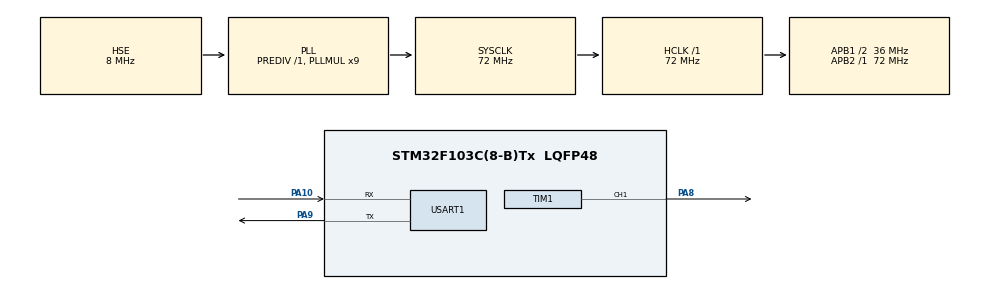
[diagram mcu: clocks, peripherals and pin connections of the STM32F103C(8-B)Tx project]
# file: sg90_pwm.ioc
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Mcu.Family=STM32F1
Mcu.Name=STM32F103C(8-B)Tx
Mcu.Package=LQFP48
NVIC.PriorityGroup=NVIC_PRIORITYGROUP_4
NVIC.USART1_IRQn=true\:0\:0\:false\:false\:true\:true\:true\:true
PA10.Mode=Asynchronous
PA10.Signal=USART1_RX
PA13.Mode=Serial_Wire
PA13.Signal=SYS_JTMS-SWDIO
PA14.Mode=Serial_Wire
PA14.Signal=SYS_JTCK-SWCLK
PA8.Signal=S_TIM1_CH1
PA9.Mode=Asynchronous
PA9.Signal=USART1_TX
PD0-OSC_IN.Mode=HSE-External-Oscillator
PD0-OSC_IN.Signal=RCC_OSC_IN
PD1-OSC_OUT.Mode=HSE-External-Oscillator
PD1-OSC_OUT.Signal=RCC_OSC_OUT
ProjectManager.HeapSize=0x200
ProjectManager.StackSize=0x400
ProjectManager.TargetToolchain=MDK-ARM V5.32
RCC.AHBFreq_Value=72000000
RCC.APB1CLKDivider=RCC_HCLK_DIV2
RCC.APB1Freq_Value=36000000
RCC.APB1TimFreq_Value=72000000
RCC.APB2Freq_Value=72000000
RCC.APB2TimFreq_Value=72000000
RCC.HCLKFreq_Value=72000000
RCC.PLLMUL=RCC_PLL_MUL9
RCC.PLLSourceVirtual=RCC_PLLSOURCE_HSE
RCC.SYSCLKFreq_VALUE=72000000
RCC.SYSCLKSource=RCC_SYSCLKSOURCE_PLLCLK
RCC.USBFreq_Value=72000000
SH.S_TIM1_CH1.0=TIM1_CH1,PWM Generation1 CH1
TIM1.AutoReloadPreload=TIM_AUTORELOAD_PRELOAD_ENABLE
TIM1.Channel-PWM\ Generation1\ CH1=TIM_CHANNEL_1
TIM1.OCFastMode_PWM-PWM\ Generation1\ CH1=TIM_OCFAST_ENABLE
TIM1.Period=19999
TIM1.Prescaler=71
TIM1.Pulse-PWM\ Generation1\ CH1=1000-1
USART1.VirtualMode=VM_ASYNC
board=custom

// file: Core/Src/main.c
/* USER CODE BEGIN Header */
/**
  ******************************************************************************
  * @file           : main.c
  * @brief          : Main program body
  ******************************************************************************
  * @attention
  *
  * Copyright (c) 2026 STMicroelectronics.
  * All rights reserved.
  *
  * This software is licensed under terms that can be found in the LICENSE file
  * in the root directory of this software component.
  * If no LICENSE file comes with this software, it is provided AS-IS.
  *
  ******************************************************************************
  */
/* USER CODE END Header */
#include "main.h"
#include "tim.h"
#include "usart.h"
#include "gpio.h"

/* USER CODE BEGIN Includes */
#include <string.h>
#include <stdlib.h>
#include <stdio.h>
/* USER CODE END Includes */

/* USER CODE BEGIN PV */
uint8_t rx_byte;
char rx_buf[32];
uint8_t rx_index =0;
/* USER CODE END PV */

void SystemClock_Config(void);
/* USER CODE BEGIN PFP */
void parse_command(char *cmd);   // 指令解析函数声明
/* USER CODE END PFP */

int main(void)
{

  /* MCU Configuration--------------------------------------------------------*/

  /* Reset of all peripherals, Initializes the Flash interface and the Systick. */
  HAL_Init();

  /* Configure the system clock */
  SystemClock_Config();

  /* Initialize all configured peripherals */
  MX_GPIO_Init();
  MX_TIM1_Init();
  MX_USART1_UART_Init();
  /* USER CODE BEGIN 2 */
  HAL_TIM_PWM_Start(&htim1, TIM_CHANNEL_1);
  HAL_UART_Receive_IT(&huart1, &rx_byte, 1);
  // 上电打印测试信息
  HAL_UART_Transmit(&huart1, (uint8_t*)"SG90 Servo Ready\r\n", 18, 100);
  /* USER CODE END 2 */

  /* Infinite loop */
  while (1)
  {

    /* USER CODE BEGIN 3 */
    // 什么都不用做，接收全部在中断回调里处理
  }
  /* USER CODE END 3 */
}

void SystemClock_Config(void)
{
  RCC_OscInitTypeDef RCC_OscInitStruct = {0};
  RCC_ClkInitTypeDef RCC_ClkInitStruct = {0};

  /** Initializes the RCC Oscillators according to the specified parameters
  * in the RCC_OscInitTypeDef structure.
  */
  RCC_OscInitStruct.OscillatorType = RCC_OSCILLATORTYPE_HSE;
  RCC_OscInitStruct.HSEState = RCC_HSE_ON;
  RCC_OscInitStruct.HSEPredivValue = RCC_HSE_PREDIV_DIV1;
  RCC_OscInitStruct.HSIState = RCC_HSI_ON;
  RCC_OscInitStruct.PLL.PLLState = RCC_PLL_ON;
  RCC_OscInitStruct.PLL.PLLSource = RCC_PLLSOURCE_HSE;
  RCC_OscInitStruct.PLL.PLLMUL = RCC_PLL_MUL9;
  if (HAL_RCC_OscConfig(&RCC_OscInitStruct) != HAL_OK)
  {
    Error_Handler();
  }

  /** Initializes the CPU, AHB and APB buses clocks
  */
  RCC_ClkInitStruct.ClockType = RCC_CLOCKTYPE_HCLK|RCC_CLOCKTYPE_SYSCLK
                              |RCC_CLOCKTYPE_PCLK1|RCC_CLOCKTYPE_PCLK2;
  RCC_ClkInitStruct.SYSCLKSource = RCC_SYSCLKSOURCE_PLLCLK;
  RCC_ClkInitStruct.AHBCLKDivider = RCC_SYSCLK_DIV1;
  RCC_ClkInitStruct.APB1CLKDivider = RCC_HCLK_DIV2;
  RCC_ClkInitStruct.APB2CLKDivider = RCC_HCLK_DIV1;

  if (HAL_RCC_ClockConfig(&RCC_ClkInitStruct, FLASH_LATENCY_2) != HAL_OK)
  {
    Error_Handler();
  }
}

/* USER CODE BEGIN 4 */
// 指令解析函数
// 指令格式: "angle: XXX" (XXX 为 0-180 的整数)
void parse_command(char *cmd)
{
    // 匹配 "angle:" 前缀
    if(strncmp(cmd, "angle:", 6) == 0)
    {
        char *num_str = cmd + 6;   // 跳过"angle:"，指向数字部分
        int angle = atoi(num_str);

        if(angle < 0 || angle > 180)
        {
            // 角度超范围错误提示
            char msg[] = "Angle range error, only 0-180\r\n";
            HAL_UART_Transmit(&huart1, (uint8_t*)msg, strlen(msg), 100);
        }
        else
        {
            // 计算PWM占空比：0度→500，180度→2500
            int ccr = 500 + angle * 2000 / 180;
            __HAL_TIM_SET_COMPARE(&htim1, TIM_CHANNEL_1, ccr);

            // 回发成功信息
            char msg[64];
            sprintf(msg, "Servo moved to %d deg\r\n", angle);
            HAL_UART_Transmit(&huart1, (uint8_t*)msg, strlen(msg), 100);
        }
    }
    else
    {
        // 指令格式错误提示
        char msg[] = "Command format error, please retry\r\n";
        HAL_UART_Transmit(&huart1, (uint8_t*)msg, strlen(msg), 100);
    }
}

void HAL_UART_RxCpltCallback(UART_HandleTypeDef *huart)
{
    if(huart->Instance == USART1)
    {
        // 收到回车或换行，认为一条指令结束
        if(rx_byte == '\n' || rx_byte == '\r' || rx_index >= 30)
        {
            if(rx_index > 0)
            {
                rx_buf[rx_index] = '\0';
                parse_command(rx_buf);   // 解析指令
            }
            rx_index = 0;
        }
        else
        {
            rx_buf[rx_index++] = rx_byte;
        }

        // 重新开启下一次接收中断
        HAL_UART_Receive_IT(&huart1, &rx_byte, 1);
    }
}
/* USER CODE END 4 */

void Error_Handler(void)
{
  __disable_irq();
  while (1)
  {
  }
}
